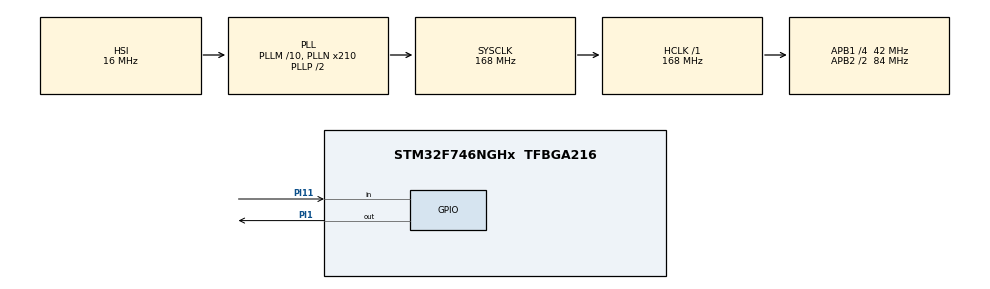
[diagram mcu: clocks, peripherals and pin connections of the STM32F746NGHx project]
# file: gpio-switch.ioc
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Mcu.Family=STM32F7
RCC.PLLSourceVirtual=RCC_PLLSOURCE_HSI
RCC.CortexFreq_Value=168000000
RCC.APB1CLKDivider=RCC_HCLK_DIV4
RCC.SYSCLKSource=RCC_SYSCLKSOURCE_PLLCLK
ProjectManager.StackSize=0x400
ProjectManager.TargetToolchain=STM32CubeIDE
RCC.HCLKFreq_Value=168000000
RCC.APB2TimFreq_Value=168000000
RCC.USBFreq_Value=168000000
RCC.LSE_VALUE=32768
RCC.AHBFreq_Value=168000000
RCC.HSE_VALUE=25000000
board=STM32F746G-DISCO
RCC.VCOOutputFreq_Value=336000000
RCC.APB2Freq_Value=84000000
PI1.Signal=GPIO_Output
Mcu.Name=STM32F746NGHx
RCC.SYSCLKFreq_VALUE=168000000
Mcu.Package=TFBGA216
ProjectManager.HeapSize=0x200
RCC.HSI_VALUE=16000000
NVIC.PriorityGroup=NVIC_PRIORITYGROUP_4
RCC.APB2CLKDivider=RCC_HCLK_DIV2
RCC.PLLM=10
RCC.PLLN=210
RCC.APB1TimFreq_Value=84000000
PI11.Signal=GPIO_Input
RCC.APB1Freq_Value=42000000

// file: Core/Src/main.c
/* USER CODE BEGIN Header */
/**
  ******************************************************************************
  * @file           : main.c
  * @brief          : Main program body
  ******************************************************************************
  * @attention
  *
  * <h2><center>&copy; Copyright (c) 2021 STMicroelectronics.
  * All rights reserved.</center></h2>
  *
  * This software component is licensed by ST under BSD 3-Clause license,
  * the "License"; You may not use this file except in compliance with the
  * License. You may obtain a copy of the License at:
  *                        opensource.org/licenses/BSD-3-Clause
  *
  ******************************************************************************
  */
/* USER CODE END Header */
#include "main.h"

void SystemClock_Config(void);
static void MX_GPIO_Init(void);

int main(void)
{

  /* MCU Configuration--------------------------------------------------------*/

  /* Reset of all peripherals, Initializes the Flash interface and the Systick. */
  HAL_Init();

  /* Configure the system clock */
  SystemClock_Config();

  /* Initialize all configured peripherals */
  MX_GPIO_Init();

  /* Infinite loop */
  /* USER CODE BEGIN WHILE */
  while (1)
  {
	  if (HAL_GPIO_ReadPin(GPIOI, GPIO_PIN_11) == GPIO_PIN_SET)
	  {
		  HAL_GPIO_WritePin(GPIOI, GPIO_PIN_1, GPIO_PIN_SET);
	  }
	  else
	  {
		  HAL_GPIO_WritePin(GPIOI, GPIO_PIN_1, GPIO_PIN_RESET);
	  }
    /* USER CODE END WHILE */

  }
}

void SystemClock_Config(void)
{
  RCC_OscInitTypeDef RCC_OscInitStruct = {0};
  RCC_ClkInitTypeDef RCC_ClkInitStruct = {0};

  /** Configure the main internal regulator output voltage
  */
  __HAL_RCC_PWR_CLK_ENABLE();
  __HAL_PWR_VOLTAGESCALING_CONFIG(PWR_REGULATOR_VOLTAGE_SCALE2);
  /** Initializes the RCC Oscillators according to the specified parameters
  * in the RCC_OscInitTypeDef structure.
  */
  RCC_OscInitStruct.OscillatorType = RCC_OSCILLATORTYPE_HSI;
  RCC_OscInitStruct.HSIState = RCC_HSI_ON;
  RCC_OscInitStruct.HSICalibrationValue = RCC_HSICALIBRATION_DEFAULT;
  RCC_OscInitStruct.PLL.PLLState = RCC_PLL_ON;
  RCC_OscInitStruct.PLL.PLLSource = RCC_PLLSOURCE_HSI;
  RCC_OscInitStruct.PLL.PLLM = 10;
  RCC_OscInitStruct.PLL.PLLN = 210;
  RCC_OscInitStruct.PLL.PLLP = RCC_PLLP_DIV2;
  RCC_OscInitStruct.PLL.PLLQ = 2;
  if (HAL_RCC_OscConfig(&RCC_OscInitStruct) != HAL_OK)
  {
    Error_Handler();
  }
  /** Initializes the CPU, AHB and APB buses clocks
  */
  RCC_ClkInitStruct.ClockType = RCC_CLOCKTYPE_HCLK|RCC_CLOCKTYPE_SYSCLK
                              |RCC_CLOCKTYPE_PCLK1|RCC_CLOCKTYPE_PCLK2;
  RCC_ClkInitStruct.SYSCLKSource = RCC_SYSCLKSOURCE_PLLCLK;
  RCC_ClkInitStruct.AHBCLKDivider = RCC_SYSCLK_DIV1;
  RCC_ClkInitStruct.APB1CLKDivider = RCC_HCLK_DIV4;
  RCC_ClkInitStruct.APB2CLKDivider = RCC_HCLK_DIV2;

  if (HAL_RCC_ClockConfig(&RCC_ClkInitStruct, FLASH_LATENCY_5) != HAL_OK)
  {
    Error_Handler();
  }
}

static void MX_GPIO_Init(void)
{
  GPIO_InitTypeDef GPIO_InitStruct = {0};

  /* GPIO Ports Clock Enable */
  __HAL_RCC_GPIOI_CLK_ENABLE();

  /*Configure GPIO pin Output Level */
  HAL_GPIO_WritePin(GPIOI, GPIO_PIN_1, GPIO_PIN_RESET);

  /*Configure GPIO pin : PI1 */
  GPIO_InitStruct.Pin = GPIO_PIN_1;
  GPIO_InitStruct.Mode = GPIO_MODE_OUTPUT_PP;
  GPIO_InitStruct.Pull = GPIO_NOPULL;
  GPIO_InitStruct.Speed = GPIO_SPEED_FREQ_LOW;
  HAL_GPIO_Init(GPIOI, &GPIO_InitStruct);

  /*Configure GPIO pin : PI11 */
  GPIO_InitStruct.Pin = GPIO_PIN_11;
  GPIO_InitStruct.Mode = GPIO_MODE_INPUT;
  GPIO_InitStruct.Pull = GPIO_NOPULL;
  HAL_GPIO_Init(GPIOI, &GPIO_InitStruct);

}

void Error_Handler(void)
{
  __disable_irq();
  while (1)
  {
  }
}

/************************ (C) COPYRIGHT STMicroelectronics *****END OF FILE****/
